# AT32F421 register map
Vendor: Keil; Series: AT32F421; File version: 1.0
CPU: CM4 r0p1, little endian, no MPU, FPU, 4 interrupt priority bits
Registers are 32-bit, read-write, reset 0x0 unless marked. A register's access mark holds for its fields unless they carry their own. Offsets are from the block's base; [hi:lo] are bit positions; {n}, {i} and the like mark numbered series; 'fields as' and 'values as' point back to an identical list.

## FLASH — Flash memory controler
Base 0x40022000
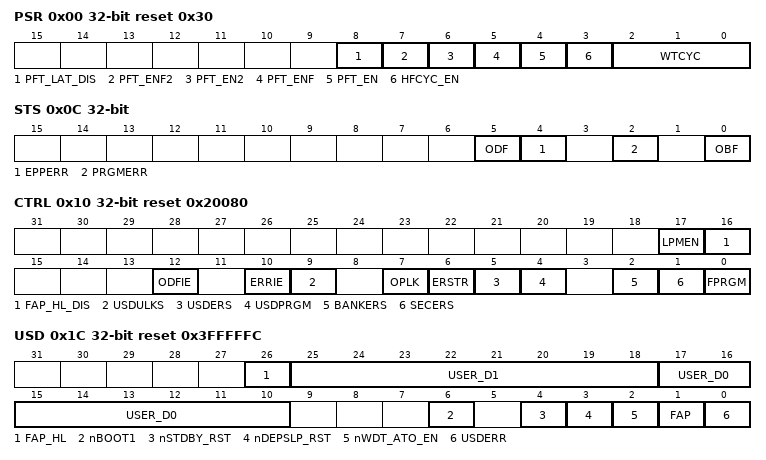
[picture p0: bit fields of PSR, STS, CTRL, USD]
0x00 PSR reset 0x30 — Performance selection register
  [8] PFT_LAT_DIS — Prefetch latency disable
  [7] PFT_ENF2 ro — Prefetch enabled flag 2
  [6] PFT_EN2 — Prefetch enable 2
  [5] PFT_ENF ro — Prefetch enabled flag
  [4] PFT_EN — Prefetch enable
  [3] HFCYC_EN — Half cycle acceleration access enable
  [2:0] WTCYC — Wait cycle
0x04 UNLOCK wo
  [31:0] UKVAL — Unlock key value
    0x45670123=Key1 (Unlock key 1); 0xCDEF89AB=Key2 (Unlock key 2)
0x08 USD_UNLOCK wo
  [31:0] USD_UKVAL — User system data Unlock key value
    values as UNLOCK.UKVAL
0x0C STS — Status register
  [5] ODF write-1-clears — Operate done flag
    0=NotSet (Flash operation done flag not set); 1=Done (Flash/erase operation done)
  [4] EPPERR write-1-clears — Erase/program protection error
    0=NoError (No erase/program error); 1=Error (Erase/program error occurred)
  [2] PRGMERR write-1-clears — program error
    0=NoError (No program error); 1=Error (Program error occurred)
  [0] OBF ro — Operate busy flag
    0=Idle (Flash is idle); 1=Busy (Flash operation is in progress)
0x10 CTRL reset 0x20080 — Control register
  [17] LPMEN — Low power mode enable
  [16] FAP_HL_DIS — FAP high level disable
  [12] ODFIE — Operation done flag interrupt enable
    0=Disabled (Operation done interrupt disabled); 1=Enabled (Operation done interrupt enabled)
  [10] ERRIE — Error interrupt enable
    0=Disabled (Error interrupt disabled); 1=Enabled (Error interrupt enabled)
  [9] USDULKS — User system data unlock success
  [7] OPLK — Operation lock
    0=Unlocked (Flash operations unlocked); 1=Locked (Flash operations locked)
  [6] ERSTR — Erasing start
    on read: 0=NotStarted (Erase operation not started); 1=Started (Erase operation is in progress) | on write: 0=NoStart (Erase operation not started); 1=Start of erase operation
  [5] USDERS — User system data erase
  [4] USDPRGM — User system data program
  [2] BANKERS — Bank erase
  [1] SECERS — Sector erase
    0=Not sector erase operation; 1=SectorErase (Erase operation is sector erase operation)
  [0] FPRGM — Flash program
    on read: 0=NotStarted (Flash program not started); 1=Started (Flash program is in progress) | on write: 0=NoStart (Flash program not started); 1=Start of flash program operation
0x14 ADDR wo — Address register
0x1C USD ro reset 0x3FFFFFC — User system data register
  [26] FAP_HL — FAP high level
  [8n+17:8n+10] USER_D{n} (n=0..1) — User data byte {n}
  [6] nBOOT1 — boot1
  [4] nSTDBY_RST — Standby reset
  [3] nDEPSLP_RST — Deepsleep reset
  [2] nWDT_ATO_EN — WDT auto enable
  [1] FAP — FLASH access protection
    0=Disabled (Flash access protection disabled); 1=Enabled (Flash access protection enabled)
  [0] USDERR — User system data error
    0=NoError (No user system data error); 1=Error (User system data error occurred. Some byte does not match it's inverse code. They both will be forced to 0xFF when read)
0x20 EPPS ro reset 0xFFFFFFFF — Erase/program protection status register
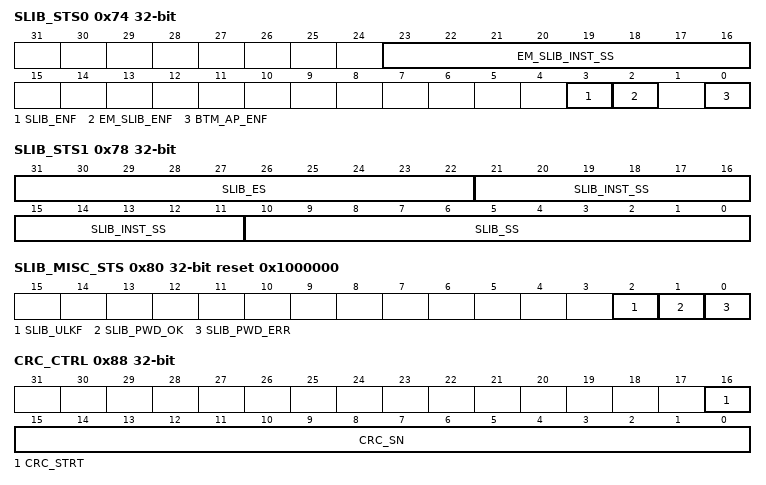
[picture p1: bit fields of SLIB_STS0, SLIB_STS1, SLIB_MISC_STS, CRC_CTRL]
0x74 SLIB_STS0 — sLib status 0 register
  [23:16] EM_SLIB_INST_SS — Extension memory sLib instruction start sector
  [3] SLIB_ENF — sLib enabled flag
  [2] EM_SLIB_ENF — Extension memory sLib enabled flag
  [0] BTM_AP_ENF — Boot memory store application code enabled flag
0x78 SLIB_STS1 — sLib status 1 register
  [31:22] SLIB_ES — sLib end sector
  [21:11] SLIB_INST_SS — sLib instruction start sector
  [10:0] SLIB_SS — sLib start sector
0x7C SLIB_PWD_CLR wo — SLIB password clear register
  [31:0] SLIB_PCLR_VAL — sLib password clear value
0x80 SLIB_MISC_STS reset 0x1000000 — sLib misc status register
  [2] SLIB_ULKF ro — sLib unlock flag
  [1] SLIB_PWD_OK ro — sLib password ok
  [0] SLIB_PWD_ERR ro — sLib password error
0x84 CRC_ADDR wo — Flash CRC data start address register
  [31:0] CRC_ADDR — CRC address
0x88 CRC_CTRL — Flash CRC controll register
  [16] CRC_STRT wo — CRC start
  [15:0] CRC_SN — CRC sector numbler
0x8C CRC_CHKR ro — FLASH CRC check result register
  [31:0] FCRC_OUT — CRC32 verification result of flash user code or SLIB code
0x160 SLIB_SET_PWD wo — sLib password setting register
  [31:0] SLIB_PSET_VAL — sLib password setting val
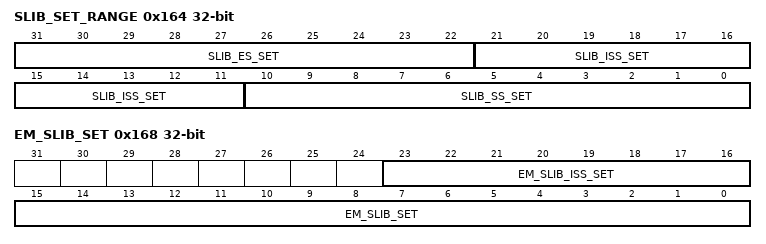
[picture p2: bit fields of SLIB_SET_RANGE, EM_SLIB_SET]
0x164 SLIB_SET_RANGE wo — Configure sLib range register
  [31:22] SLIB_ES_SET — sLib end sector setting
  [21:11] SLIB_ISS_SET — sLib instruction start sector setting
  [10:0] SLIB_SS_SET — sLib start sector setting
0x168 EM_SLIB_SET wo — Extension momery slib set register
  [23:16] EM_SLIB_ISS_SET — Extension memory sLib instruction start sector setting
  [15:0] EM_SLIB_SET — Extension memory sLib setting
0x16C BTM_MODE_SET wo — Boot memory mode setting register
  [7:0] BTM_MODE_SET — Boot memory mode setting
0x170 SLIB_UNLOCK wo
  [31:0] SLIB_UKVAL — sLib unlock key value
